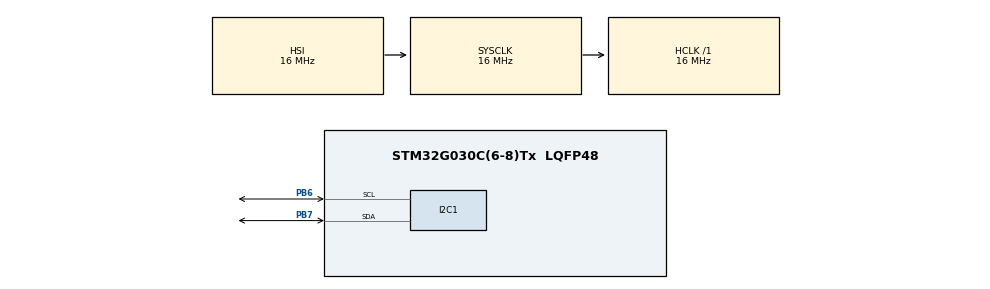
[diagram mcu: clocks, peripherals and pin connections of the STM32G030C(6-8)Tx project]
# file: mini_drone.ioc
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Mcu.Family=STM32G0
Mcu.Name=STM32G030C(6-8)Tx
Mcu.Package=LQFP48
PB6.Mode=I2C
PB6.Signal=I2C1_SCL
PB7.Mode=I2C
PB7.Signal=I2C1_SDA
PF0-OSC_IN\ (PF0).Mode=HSE-External-Oscillator
PF0-OSC_IN\ (PF0).Signal=RCC_OSC_IN
PF1-OSC_OUT\ (PF1).Mode=HSE-External-Oscillator
PF1-OSC_OUT\ (PF1).Signal=RCC_OSC_OUT
ProjectManager.HeapSize=0x200
ProjectManager.StackSize=0x400
ProjectManager.TargetToolchain=STM32CubeIDE
RCC.AHBFreq_Value=16000000
RCC.CortexFreq_Value=16000000
RCC.EXTERNAL_CLOCK_VALUE=12288000
RCC.HCLKFreq_Value=16000000
RCC.HSE_VALUE=8000000
RCC.HSI_VALUE=16000000
RCC.LSE_VALUE=32768
RCC.SYSCLKFreq_VALUE=16000000
RCC.VCOOutputFreq_Value=128000000
board=custom

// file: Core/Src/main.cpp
/* USER CODE BEGIN Header */
/**
  ******************************************************************************
  * @file           : main.c
  * @brief          : Main program body
  ******************************************************************************
  * @attention
  *
  * <h2><center>&copy; Copyright (c) 2021 STMicroelectronics.
  * All rights reserved.</center></h2>
  *
  * This software component is licensed by ST under BSD 3-Clause license,
  * the "License"; You may not use this file except in compliance with the
  * License. You may obtain a copy of the License at:
  *                        opensource.org/licenses/BSD-3-Clause
  *
  ******************************************************************************
  */
/* USER CODE END Header */
#include "main.h"

/* USER CODE BEGIN Includes */
#define ARM_MATH_CM0

#include "arm_math.h"
#include "mpu9250.hpp"
#include "EKF2.h"
#include "calib_magnet.h"
/* USER CODE END Includes */

I2C_HandleTypeDef hi2c1;

void SystemClock_Config(void);
static void MX_GPIO_Init(void);
static void MX_I2C1_Init(void);

IMU_data data_imu_temp;
IMU_data data_imu_raw;
IMU_data data_imu_buffer;
IMU_data data_imu_com;
MAG_data mag;
float dt = 0.01;
EKF2 ekf;

/* USER CODE END 0 */

int main(void)
{

  /* MCU Configuration--------------------------------------------------------*/

  /* Reset of all peripherals, Initializes the Flash interface and the Systick. */
  HAL_Init();

  /* Configure the system clock */
  SystemClock_Config();

  /* Initialize all configured peripherals */
  MX_GPIO_Init();
  MX_I2C1_Init();
  /* USER CODE BEGIN 2 */
  ekf.x_[4] = bGx * DEC2RAD;
   ekf.x_[5] = bGy * DEC2RAD;
   ekf.x_[6] = bGz * DEC2RAD;

 //  ekf.x4 = bGx * DEC2RAD;
 //   ekf.x4 = bGy * DEC2RAD;
 //   ekf.x6 = bGz * DEC2RAD;

   ekf.loadEKF();
  /* USER CODE END 2 */

  /* Infinite loop */
  while (1)
  {

    /* USER CODE BEGIN 3 */
	  ekf.updateEKF(data_imu_buffer,mag, 0.01);
  }
  /* USER CODE END 3 */
}

void SystemClock_Config(void)
{
  RCC_OscInitTypeDef RCC_OscInitStruct = {0};
  RCC_ClkInitTypeDef RCC_ClkInitStruct = {0};
  RCC_PeriphCLKInitTypeDef PeriphClkInit = {0};

  /** Configure the main internal regulator output voltage
  */
  HAL_PWREx_ControlVoltageScaling(PWR_REGULATOR_VOLTAGE_SCALE1);
  /** Initializes the RCC Oscillators according to the specified parameters
  * in the RCC_OscInitTypeDef structure.
  */
  RCC_OscInitStruct.OscillatorType = RCC_OSCILLATORTYPE_HSI;
  RCC_OscInitStruct.HSIState = RCC_HSI_ON;
  RCC_OscInitStruct.HSIDiv = RCC_HSI_DIV1;
  RCC_OscInitStruct.HSICalibrationValue = RCC_HSICALIBRATION_DEFAULT;
  RCC_OscInitStruct.PLL.PLLState = RCC_PLL_NONE;
  if (HAL_RCC_OscConfig(&RCC_OscInitStruct) != HAL_OK)
  {
    Error_Handler();
  }
  /** Initializes the CPU, AHB and APB buses clocks
  */
  RCC_ClkInitStruct.ClockType = RCC_CLOCKTYPE_HCLK|RCC_CLOCKTYPE_SYSCLK
                              |RCC_CLOCKTYPE_PCLK1;
  RCC_ClkInitStruct.SYSCLKSource = RCC_SYSCLKSOURCE_HSI;
  RCC_ClkInitStruct.AHBCLKDivider = RCC_SYSCLK_DIV1;
  RCC_ClkInitStruct.APB1CLKDivider = RCC_HCLK_DIV1;

  if (HAL_RCC_ClockConfig(&RCC_ClkInitStruct, FLASH_LATENCY_0) != HAL_OK)
  {
    Error_Handler();
  }
  /** Initializes the peripherals clocks
  */
  PeriphClkInit.PeriphClockSelection = RCC_PERIPHCLK_I2C1;
  PeriphClkInit.I2c1ClockSelection = RCC_I2C1CLKSOURCE_PCLK1;
  if (HAL_RCCEx_PeriphCLKConfig(&PeriphClkInit) != HAL_OK)
  {
    Error_Handler();
  }
}

static void MX_I2C1_Init(void)
{

  hi2c1.Instance = I2C1;
  hi2c1.Init.Timing = 0x00303D5B;
  hi2c1.Init.OwnAddress1 = 0;
  hi2c1.Init.AddressingMode = I2C_ADDRESSINGMODE_7BIT;
  hi2c1.Init.DualAddressMode = I2C_DUALADDRESS_DISABLE;
  hi2c1.Init.OwnAddress2 = 0;
  hi2c1.Init.OwnAddress2Masks = I2C_OA2_NOMASK;
  hi2c1.Init.GeneralCallMode = I2C_GENERALCALL_DISABLE;
  hi2c1.Init.NoStretchMode = I2C_NOSTRETCH_DISABLE;
  if (HAL_I2C_Init(&hi2c1) != HAL_OK)
  {
    Error_Handler();
  }
  /** Configure Analogue filter
  */
  if (HAL_I2CEx_ConfigAnalogFilter(&hi2c1, I2C_ANALOGFILTER_ENABLE) != HAL_OK)
  {
    Error_Handler();
  }
  /** Configure Digital filter
  */
  if (HAL_I2CEx_ConfigDigitalFilter(&hi2c1, 0) != HAL_OK)
  {
    Error_Handler();
  }

}

static void MX_GPIO_Init(void)
{

  /* GPIO Ports Clock Enable */
  __HAL_RCC_GPIOF_CLK_ENABLE();
  __HAL_RCC_GPIOB_CLK_ENABLE();

}

void Error_Handler(void)
{
  __disable_irq();
  while (1)
  {
  }
}

/************************ (C) COPYRIGHT STMicroelectronics *****END OF FILE****/
